# STM32H725ZGT7 register map
File version: 1.0
Registers are 32-bit, access not given, reset 0x0 unless marked. A register's access mark holds for its fields unless they carry their own. Offsets are from the block's base; [hi:lo] are bit positions; {n}, {i} and the like mark numbered series.

## RNG
Base 0x48021800
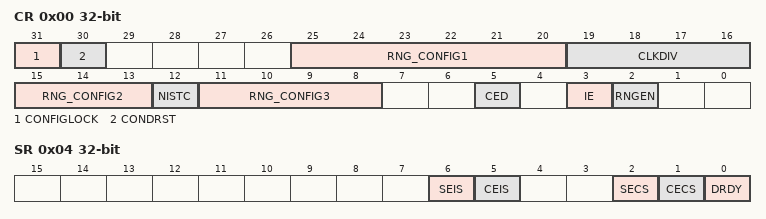
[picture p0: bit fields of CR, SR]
0x00 CR
  [31] CONFIGLOCK, [30] CONDRST, [25:20] RNG_CONFIG1, [19:16] CLKDIV, [15:13] RNG_CONFIG2, [12] NISTC, [11:8] RNG_CONFIG3, [5] CED, [3] IE, [2] RNGEN
0x04 SR
  [6] SEIS, [5] CEIS, [2] SECS, [1] CECS, [0] DRDY
0x08 DR
0x10 HTCR

## SDMMC2
Base 0x48022400
Same registers: SDMMC1 0x52007000
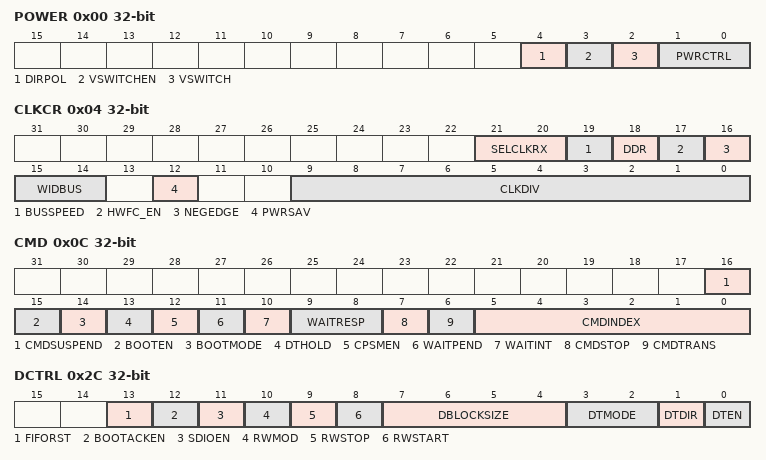
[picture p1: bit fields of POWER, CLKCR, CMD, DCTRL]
0x00 POWER
  [4] DIRPOL, [3] VSWITCHEN, [2] VSWITCH, [1:0] PWRCTRL
0x04 CLKCR
  [21:20] SELCLKRX, [19] BUSSPEED, [18] DDR, [17] HWFC_EN, [16] NEGEDGE, [15:14] WIDBUS, [12] PWRSAV, [9:0] CLKDIV
0x08 ARG
  [31:0] CMDARG
0x0C CMD
  [16] CMDSUSPEND, [15] BOOTEN, [14] BOOTMODE, [13] DTHOLD, [12] CPSMEN, [11] WAITPEND, [10] WAITINT, [9:8] WAITRESP, [7] CMDSTOP, [6] CMDTRANS, [5:0] CMDINDEX
0x10 RESPCMD
  [5:0] RESPCMD
{0x10+4i} RESP{i} (i=1..4)
  [31:0] CARDSTATUS{i}
0x24 DTIMER
  [31:0] DATATIME
0x28 DLEN
  [24:0] DATALENGTH
0x2C DCTRL
  [13] FIFORST, [12] BOOTACKEN, [11] SDIOEN, [10] RWMOD, [9] RWSTOP, [8] RWSTART, [7:4] DBLOCKSIZE, [3:2] DTMODE, [1] DTDIR, [0] DTEN
0x30 DCOUNT
  [24:0] DATACOUNT
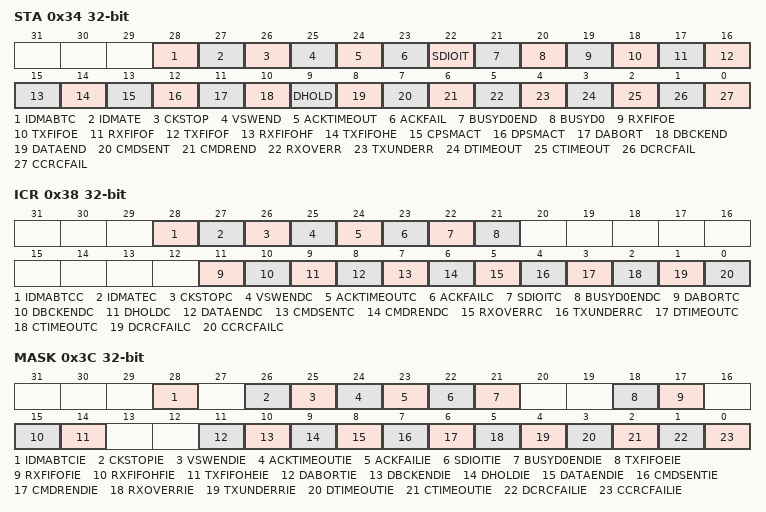
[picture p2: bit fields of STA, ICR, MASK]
0x34 STA
  [28] IDMABTC, [27] IDMATE, [26] CKSTOP, [25] VSWEND, [24] ACKTIMEOUT, [23] ACKFAIL, [22] SDIOIT, [21] BUSYD0END, [20] BUSYD0, [19] RXFIFOE, [18] TXFIFOE, [17] RXFIFOF, [16] TXFIFOF, [15] RXFIFOHF, [14] TXFIFOHE, [13] CPSMACT, [12] DPSMACT, [11] DABORT, [10] DBCKEND, [9] DHOLD, [8] DATAEND, [7] CMDSENT, [6] CMDREND, [5] RXOVERR, [4] TXUNDERR, [3] DTIMEOUT, [2] CTIMEOUT, [1] DCRCFAIL, [0] CCRCFAIL
0x38 ICR
  [28] IDMABTCC, [27] IDMATEC, [26] CKSTOPC, [25] VSWENDC, [24] ACKTIMEOUTC, [23] ACKFAILC, [22] SDIOITC, [21] BUSYD0ENDC, [11] DABORTC, [10] DBCKENDC, [9] DHOLDC, [8] DATAENDC, [7] CMDSENTC, [6] CMDRENDC, [5] RXOVERRC, [4] TXUNDERRC, [3] DTIMEOUTC, [2] CTIMEOUTC, [1] DCRCFAILC, [0] CCRCFAILC
0x3C MASK
  [28] IDMABTCIE, [26] CKSTOPIE, [25] VSWENDIE, [24] ACKTIMEOUTIE, [23] ACKFAILIE, [22] SDIOITIE, [21] BUSYD0ENDIE, [18] TXFIFOEIE, [17] RXFIFOFIE, [15] RXFIFOHFIE, [14] TXFIFOHEIE, [11] DABORTIE, [10] DBCKENDIE, [9] DHOLDIE, [8] DATAENDIE, [7] CMDSENTIE, [6] CMDRENDIE, [5] RXOVERRIE, [4] TXUNDERRIE, [3] DTIMEOUTIE, [2] CTIMEOUTIE, [1] DCRCFAILIE, [0] CCRCFAILIE
0x40 ACKTIME
  [24:0] ACKTIME
0x50 IDMACTRL
0x54 IDMABSIZE
  [12:5] IDMABNDT
0x58 IDMABASE0
0x5C IDMABASE1
0x80 FIFO
  [31:0] FIFODATA
0x3FC IPVR

## DLYB_SDMMC2
Base 0x48022800
Same registers: DLYB_OCTOSPI1 0x52006000, DLYB_SDMMC1 0x52008000, DLYB_OCTOSPI2 0x5200B000
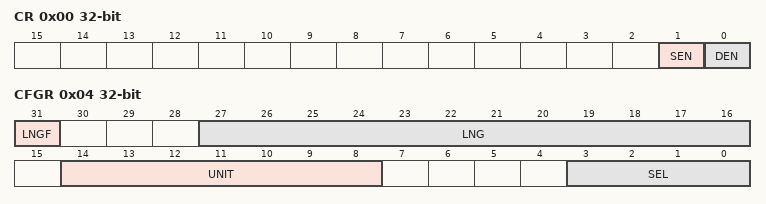
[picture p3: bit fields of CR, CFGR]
0x00 CR
  [1] SEN, [0] DEN
0x04 CFGR
  [31] LNGF, [27:16] LNG, [14:8] UNIT, [3:0] SEL

## RAMECC2
Base 0x48023000
Same registers: RAMECC1 0x52009000, RAMECC3 0x58027000
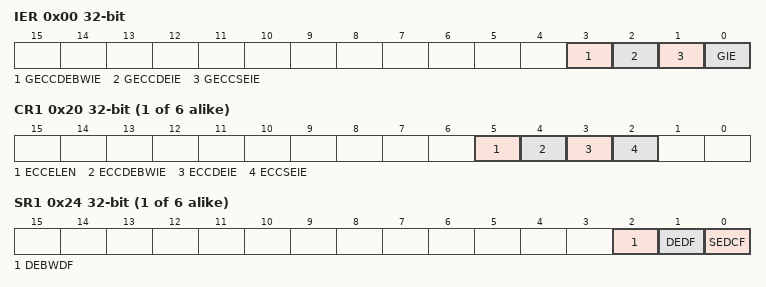
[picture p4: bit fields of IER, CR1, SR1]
0x00 IER
  [3] GECCDEBWIE, [2] GECCDEIE, [1] GECCSEIE, [0] GIE
{0x0+0x20*i} CR{i} (i=1..6)
  [5] ECCELEN, [4] ECCDEBWIE, [3] ECCDEIE, [2] ECCSEIE
{0x4+0x20*i} SR{i} (i=1..6)
  [2] DEBWDF, [1] DEDF, [0] SEDCF
{0x8+0x20*i} FAR{i} (i=1..6)
  [31:0] FDATAL
{0xC+0x20*i} FDRL{i} (i=1..6)
{0x10+0x20*i} FDRH{i} (i=1..6)
{0x14+0x20*i} FECR{i} (i=1..6)
  [31:0] FEC

## FMAC
Base 0x48024000
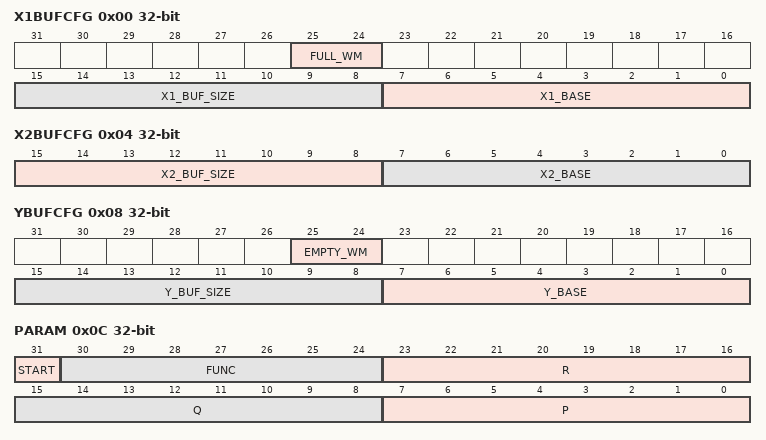
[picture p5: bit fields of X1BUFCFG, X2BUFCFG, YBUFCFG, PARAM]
0x00 X1BUFCFG
  [25:24] FULL_WM, [15:8] X1_BUF_SIZE, [7:0] X1_BASE
0x04 X2BUFCFG
  [15:8] X2_BUF_SIZE, [7:0] X2_BASE
0x08 YBUFCFG
  [25:24] EMPTY_WM, [15:8] Y_BUF_SIZE, [7:0] Y_BASE
0x0C PARAM
  [31] START, [30:24] FUNC, [23:16] R, [15:8] Q, [7:0] P
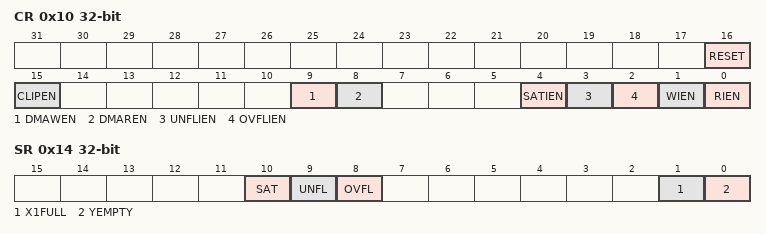
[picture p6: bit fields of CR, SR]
0x10 CR
  [16] RESET, [15] CLIPEN, [9] DMAWEN, [8] DMAREN, [4] SATIEN, [3] UNFLIEN, [2] OVFLIEN, [1] WIEN, [0] RIEN
0x14 SR
  [10] SAT, [9] UNFL, [8] OVFL, [1] X1FULL, [0] YEMPTY
0x18 WDATA
  [15:0] WDATA
0x1C RDATA
  [15:0] RDATA

## CORDIC
Base 0x48024400
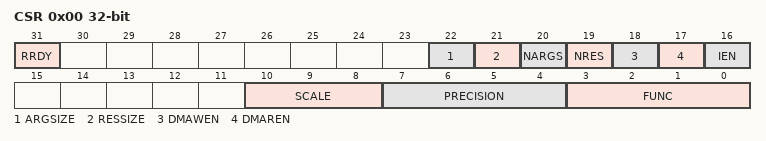
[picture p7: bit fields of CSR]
0x00 CSR
  [31] RRDY, [22] ARGSIZE, [21] RESSIZE, [20] NARGS, [19] NRES, [18] DMAWEN, [17] DMAREN, [16] IEN, [10:8] SCALE, [7:4] PRECISION, [3:0] FUNC
0x04 WDATA
  [31:0] ARG
0x08 RDATA
  [31:0] RES
